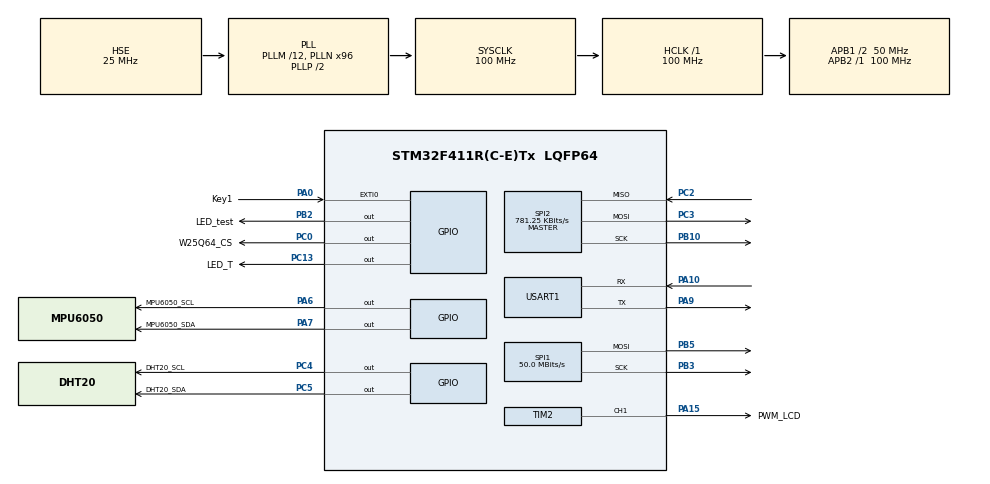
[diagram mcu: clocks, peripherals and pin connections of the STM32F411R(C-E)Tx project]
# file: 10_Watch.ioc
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Dma.Request0=SPI1_TX
Dma.Request1=USART1_RX
Dma.Request2=USART1_TX
Dma.Request3=SPI2_RX
Dma.Request4=SPI2_TX
Dma.SPI1_TX.0.Direction=DMA_MEMORY_TO_PERIPH
Dma.SPI1_TX.0.FIFOMode=DMA_FIFOMODE_DISABLE
Dma.SPI1_TX.0.Instance=DMA2_Stream2
Dma.SPI1_TX.0.MemDataAlignment=DMA_MDATAALIGN_BYTE
Dma.SPI1_TX.0.MemInc=DMA_MINC_ENABLE
Dma.SPI1_TX.0.Mode=DMA_NORMAL
Dma.SPI1_TX.0.PeriphDataAlignment=DMA_PDATAALIGN_BYTE
Dma.SPI1_TX.0.PeriphInc=DMA_PINC_DISABLE
Dma.SPI1_TX.0.Priority=DMA_PRIORITY_LOW
Dma.SPI2_RX.3.Direction=DMA_PERIPH_TO_MEMORY
Dma.SPI2_RX.3.FIFOMode=DMA_FIFOMODE_DISABLE
Dma.SPI2_RX.3.Instance=DMA1_Stream3
Dma.SPI2_RX.3.MemDataAlignment=DMA_MDATAALIGN_BYTE
Dma.SPI2_RX.3.MemInc=DMA_MINC_ENABLE
Dma.SPI2_RX.3.Mode=DMA_NORMAL
Dma.SPI2_RX.3.PeriphDataAlignment=DMA_PDATAALIGN_BYTE
Dma.SPI2_RX.3.PeriphInc=DMA_PINC_DISABLE
Dma.SPI2_RX.3.Priority=DMA_PRIORITY_LOW
Dma.SPI2_TX.4.Direction=DMA_MEMORY_TO_PERIPH
Dma.SPI2_TX.4.FIFOMode=DMA_FIFOMODE_DISABLE
Dma.SPI2_TX.4.Instance=DMA1_Stream4
Dma.SPI2_TX.4.MemDataAlignment=DMA_MDATAALIGN_BYTE
Dma.SPI2_TX.4.MemInc=DMA_MINC_ENABLE
Dma.SPI2_TX.4.Mode=DMA_NORMAL
Dma.SPI2_TX.4.PeriphDataAlignment=DMA_PDATAALIGN_BYTE
Dma.SPI2_TX.4.PeriphInc=DMA_PINC_DISABLE
Dma.SPI2_TX.4.Priority=DMA_PRIORITY_LOW
Dma.USART1_RX.1.Direction=DMA_PERIPH_TO_MEMORY
Dma.USART1_RX.1.FIFOMode=DMA_FIFOMODE_DISABLE
Dma.USART1_RX.1.Instance=DMA2_Stream5
Dma.USART1_RX.1.MemDataAlignment=DMA_MDATAALIGN_BYTE
Dma.USART1_RX.1.MemInc=DMA_MINC_ENABLE
Dma.USART1_RX.1.Mode=DMA_NORMAL
Dma.USART1_RX.1.PeriphDataAlignment=DMA_PDATAALIGN_BYTE
Dma.USART1_RX.1.PeriphInc=DMA_PINC_DISABLE
Dma.USART1_RX.1.Priority=DMA_PRIORITY_LOW
Dma.USART1_TX.2.Direction=DMA_MEMORY_TO_PERIPH
Dma.USART1_TX.2.FIFOMode=DMA_FIFOMODE_DISABLE
Dma.USART1_TX.2.Instance=DMA2_Stream7
Dma.USART1_TX.2.MemDataAlignment=DMA_MDATAALIGN_BYTE
Dma.USART1_TX.2.MemInc=DMA_MINC_ENABLE
Dma.USART1_TX.2.Mode=DMA_NORMAL
Dma.USART1_TX.2.PeriphDataAlignment=DMA_PDATAALIGN_BYTE
Dma.USART1_TX.2.PeriphInc=DMA_PINC_DISABLE
Dma.USART1_TX.2.Priority=DMA_PRIORITY_LOW
FREERTOS.BinarySemaphores01=SerialBinarySem,Dynamic,NULL,Depleted;SPI2_tx_BinarySem,Dynamic,NULL,Available;SPI2_rx_BinarySem,Dynamic,NULL,Available
FREERTOS.Events01=BootEvent,Dynamic,NULL
FREERTOS.Mutexes01=SerialMutex,Dynamic,NULL,Available
FREERTOS.RecursiveMutexes01=W25Q64_RecursiveMutex,Dynamic,NULL,Available
FREERTOS.Tasks01=defaultTask,8,64,StartDefaultTask,Default,NULL,Dynamic,NULL,NULL;KeyTask,41,64,StartKeyTask,As weak,NULL,Dynamic,NULL,NULL;SerialTask,32,128,StartSerialTask,As weak,NULL,Dynamic,NULL,NULL;PageBackTask,40,128,StartPageBackTask,As weak,NULL,Dynamic,NULL,NULL;MsgInbox_Task,24,256,StartMsgInboxTask,As weak,NULL,Dynamic,NULL,NULL;IdleMonitorTask,15,128,StartIdleMonitorTask,As weak,NULL,Dynamic,NULL,NULL;Sleep_Task,8,128,StartSleepTask,As weak,NULL,Dynamic,NULL,NULL;SensorTask,24,512,StartSensorTask,As weak,NULL,Dynamic,NULL,NULL;W25Q64Task,16,1024,StartW25Q64Task,As weak,NULL,Dynamic,NULL,NULL;HardwareInitTask,47,1024,StartHardwareInitTask,As weak,NULL,Dynamic,NULL,NULL;LvHandlerTask,46,1024,StartLvHandlerTask,As weak,NULL,Dynamic,NULL,NULL
FREERTOS.Timers01=IdleTimer,IdleTimerCallback,osTimerPeriodic,As weak,NULL,Dynamic,NULL
FREERTOS.configMAX_TASK_NAME_LEN=32
FREERTOS.configMINIMAL_STACK_SIZE=64
FREERTOS.configTIMER_TASK_PRIORITY=40
FREERTOS.configTOTAL_HEAP_SIZE=32768
FREERTOS.configUSE_TICK_HOOK=1
Mcu.Family=STM32F4
Mcu.Name=STM32F411R(C-E)Tx
Mcu.Package=LQFP64
NVIC.DMA1_Stream3_IRQn=true\:5\:0\:false\:false\:true\:true\:false\:true\:true
NVIC.DMA1_Stream4_IRQn=true\:5\:0\:false\:false\:true\:true\:false\:true\:true
NVIC.DMA2_Stream2_IRQn=true\:5\:0\:false\:false\:true\:true\:false\:true\:true
NVIC.DMA2_Stream5_IRQn=true\:5\:0\:false\:false\:true\:true\:false\:true\:true
NVIC.DMA2_Stream7_IRQn=true\:5\:0\:false\:false\:true\:true\:false\:true\:true
NVIC.EXTI0_IRQn=true\:5\:0\:false\:false\:true\:true\:true\:true\:true
NVIC.PriorityGroup=NVIC_PRIORITYGROUP_4
NVIC.TIM1_TRG_COM_TIM11_IRQn=true\:15\:0\:false\:false\:true\:false\:false\:true\:true
NVIC.TimeBase=TIM1_TRG_COM_TIM11_IRQn
NVIC.TimeBaseIP=TIM11
NVIC.USART1_IRQn=true\:5\:0\:false\:false\:true\:true\:true\:true\:true
PA0-WKUP.GPIO_Label=Key1
PA0-WKUP.GPIO_ModeDefaultEXTI=GPIO_MODE_IT_FALLING
PA0-WKUP.GPIO_PuPd=GPIO_PULLUP
PA0-WKUP.Signal=GPXTI0
PA10.Mode=Asynchronous
PA10.Signal=USART1_RX
PA13.Mode=Serial_Wire
PA13.Signal=SYS_JTMS-SWDIO
PA14.Mode=Serial_Wire
PA14.Signal=SYS_JTCK-SWCLK
PA15.GPIO_Label=PWM_LCD
PA15.Signal=S_TIM2_CH1_ETR
PA6.GPIO_Label=MPU6050_SCL
PA6.Signal=GPIO_Output
PA7.GPIO_Label=MPU6050_SDA
PA7.Signal=GPIO_Output
PA9.Mode=Asynchronous
PA9.Signal=USART1_TX
PB10.GPIO_Speed=GPIO_SPEED_FREQ_HIGH
PB10.Mode=Full_Duplex_Master
PB10.Signal=SPI2_SCK
PB2.GPIO_Label=LED_test
PB2.Signal=GPIO_Output
PB3.GPIO_Speed=GPIO_SPEED_FREQ_VERY_HIGH
PB3.Mode=TX_Only_Simplex_Unidirect_Master
PB3.Signal=SPI1_SCK
PB5.Mode=TX_Only_Simplex_Unidirect_Master
PB5.Signal=SPI1_MOSI
PC0.GPIO_Label=W25Q64_CS
PC0.GPIO_PuPd=GPIO_PULLUP
PC0.PinState=GPIO_PIN_SET
PC0.Signal=GPIO_Output
PC13-ANTI_TAMP.GPIO_Label=LED_T
PC13-ANTI_TAMP.Signal=GPIO_Output
PC14-OSC32_IN.Mode=LSE-External-Oscillator
PC14-OSC32_IN.Signal=RCC_OSC32_IN
PC15-OSC32_OUT.Mode=LSE-External-Oscillator
PC15-OSC32_OUT.Signal=RCC_OSC32_OUT
PC2.GPIO_Speed=GPIO_SPEED_FREQ_HIGH
PC2.Mode=Full_Duplex_Master
PC2.Signal=SPI2_MISO
PC3.GPIO_Speed=GPIO_SPEED_FREQ_HIGH
PC3.Mode=Full_Duplex_Master
PC3.Signal=SPI2_MOSI
PC4.GPIO_Label=DHT20_SCL
PC4.GPIO_ModeDefaultOutputPP=GPIO_MODE_OUTPUT_OD
PC4.GPIO_PuPd=GPIO_PULLUP
PC4.GPIO_Speed=GPIO_SPEED_FREQ_HIGH
PC4.PinState=GPIO_PIN_SET
PC4.Signal=GPIO_Output
PC5.GPIO_Label=DHT20_SDA
PC5.GPIO_ModeDefaultOutputPP=GPIO_MODE_OUTPUT_OD
PC5.GPIO_PuPd=GPIO_PULLUP
PC5.GPIO_Speed=GPIO_SPEED_FREQ_HIGH
PC5.PinState=GPIO_PIN_SET
PC5.Signal=GPIO_Output
PH0\ -\ OSC_IN.Mode=HSE-External-Oscillator
PH0\ -\ OSC_IN.Signal=RCC_OSC_IN
PH1\ -\ OSC_OUT.Mode=HSE-External-Oscillator
PH1\ -\ OSC_OUT.Signal=RCC_OSC_OUT
ProjectManager.HeapSize=0x400
ProjectManager.StackSize=0xE00
ProjectManager.TargetToolchain=CMake
RCC.48MHZClocksFreq_Value=50000000
RCC.AHBFreq_Value=100000000
RCC.APB1CLKDivider=RCC_HCLK_DIV2
RCC.APB1Freq_Value=50000000
RCC.APB1TimFreq_Value=100000000
RCC.APB2Freq_Value=100000000
RCC.APB2TimFreq_Value=100000000
RCC.CortexFreq_Value=100000000
RCC.HCLKFreq_Value=100000000
RCC.HSE_VALUE=25000000
RCC.HSI_VALUE=16000000
RCC.PLLM=12
RCC.PLLN=96
RCC.PLLSourceVirtual=RCC_PLLSOURCE_HSE
RCC.SYSCLKFreq_VALUE=100000000
RCC.SYSCLKSource=RCC_SYSCLKSOURCE_PLLCLK
RCC.VCOOutputFreq_Value=200000000
RTC.Date=15
RTC.Format=RTC_FORMAT_BIN
RTC.Hours=12
RTC.Minutes=35
RTC.Month=RTC_MONTH_OCTOBER
RTC.Year=26
SH.S_TIM2_CH1_ETR.0=TIM2_CH1,PWM Generation1 CH1
SPI1.BaudRatePrescaler=SPI_BAUDRATEPRESCALER_2
SPI1.CLKPhase=SPI_PHASE_2EDGE
SPI1.CLKPolarity=SPI_POLARITY_HIGH
SPI1.CalculateBaudRate=50.0 MBits/s
SPI1.Direction=SPI_DIRECTION_2LINES
SPI1.Mode=SPI_MODE_MASTER
SPI1.VirtualType=VM_MASTER
SPI2.BaudRatePrescaler=SPI_BAUDRATEPRESCALER_64
SPI2.CalculateBaudRate=781.25 KBits/s
SPI2.Direction=SPI_DIRECTION_2LINES
SPI2.Mode=SPI_MODE_MASTER
SPI2.VirtualType=VM_MASTER
TIM2.Channel-PWM\ Generation1\ CH1=TIM_CHANNEL_1
TIM2.Period=300
TIM2.Prescaler=99
USART1.VirtualMode=VM_ASYNC
VP_FREERTOS_VS_CMSIS_V2.Mode=CMSIS_V2
VP_RTC_VS_RTC_Activate.Mode=RTC_Enabled
VP_RTC_VS_RTC_Calendar.Mode=RTC_Calendar
VP_SYS_VS_tim11.Mode=TIM11
VP_TIM2_VS_ClockSourceINT.Mode=Internal
board=custom

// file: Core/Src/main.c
/* USER CODE BEGIN Header */
/**
  ******************************************************************************
  * @file           : main.c
  * @brief          : Main program body
  ******************************************************************************
  * @attention
  *
  * Copyright (c) 2026 STMicroelectronics.
  * All rights reserved.
  *
  * This software is licensed under terms that can be found in the LICENSE file
  * in the root directory of this software component.
  * If no LICENSE file comes with this software, it is provided AS-IS.
  *
  ******************************************************************************
  */
/* USER CODE END Header */
#include "main.h"
#include "cmsis_os.h"
#include "dma.h"
#include "rtc.h"
#include "spi.h"
#include "tim.h"
#include "usart.h"
#include "gpio.h"

void SystemClock_Config(void);
void MX_FREERTOS_Init(void);

int main(void)
{

  /* MCU Configuration--------------------------------------------------------*/

  /* Reset of all peripherals, Initializes the Flash interface and the Systick. */
  HAL_Init();
  /* USER CODE BEGIN Init */
  //HAL_DBGMCU_EnableDBGStopMode();   /* 允许调试器在 STOP 模式下 halt 内核 */
  /* USER CODE END Init */

  /* Configure the system clock */
  SystemClock_Config();

  /* Initialize all configured peripherals */
  MX_GPIO_Init();
  MX_DMA_Init();
  MX_SPI1_Init();
  MX_USART1_UART_Init();
  MX_RTC_Init();
  MX_TIM2_Init();
  MX_SPI2_Init();

  /* Init scheduler */
  osKernelInitialize();  /* Call init function for freertos objects (in cmsis_os2.c) */
  MX_FREERTOS_Init();

  /* Start scheduler */
  osKernelStart();

  /* We should never get here as control is now taken by the scheduler */

  /* Infinite loop */
  while (1)
  {

  }
}

void SystemClock_Config(void)
{
  RCC_OscInitTypeDef RCC_OscInitStruct = {0};
  RCC_ClkInitTypeDef RCC_ClkInitStruct = {0};

  /** Configure the main internal regulator output voltage
  */
  __HAL_RCC_PWR_CLK_ENABLE();
  __HAL_PWR_VOLTAGESCALING_CONFIG(PWR_REGULATOR_VOLTAGE_SCALE1);

  /** Initializes the RCC Oscillators according to the specified parameters
  * in the RCC_OscInitTypeDef structure.
  */
  RCC_OscInitStruct.OscillatorType = RCC_OSCILLATORTYPE_LSI|RCC_OSCILLATORTYPE_HSE;
  RCC_OscInitStruct.HSEState = RCC_HSE_ON;
  RCC_OscInitStruct.LSIState = RCC_LSI_ON;
  RCC_OscInitStruct.PLL.PLLState = RCC_PLL_ON;
  RCC_OscInitStruct.PLL.PLLSource = RCC_PLLSOURCE_HSE;
  RCC_OscInitStruct.PLL.PLLM = 12;
  RCC_OscInitStruct.PLL.PLLN = 96;
  RCC_OscInitStruct.PLL.PLLP = RCC_PLLP_DIV2;
  RCC_OscInitStruct.PLL.PLLQ = 4;
  if (HAL_RCC_OscConfig(&RCC_OscInitStruct) != HAL_OK)
  {
    Error_Handler();
  }

  /** Initializes the CPU, AHB and APB buses clocks
  */
  RCC_ClkInitStruct.ClockType = RCC_CLOCKTYPE_HCLK|RCC_CLOCKTYPE_SYSCLK
                              |RCC_CLOCKTYPE_PCLK1|RCC_CLOCKTYPE_PCLK2;
  RCC_ClkInitStruct.SYSCLKSource = RCC_SYSCLKSOURCE_PLLCLK;
  RCC_ClkInitStruct.AHBCLKDivider = RCC_SYSCLK_DIV1;
  RCC_ClkInitStruct.APB1CLKDivider = RCC_HCLK_DIV2;
  RCC_ClkInitStruct.APB2CLKDivider = RCC_HCLK_DIV1;

  if (HAL_RCC_ClockConfig(&RCC_ClkInitStruct, FLASH_LATENCY_3) != HAL_OK)
  {
    Error_Handler();
  }
}

void HAL_TIM_PeriodElapsedCallback(TIM_HandleTypeDef *htim)
{
  if (htim->Instance == TIM11)
  {
    HAL_IncTick();
  }
}

void Error_Handler(void)
{
  __disable_irq();
  while (1)
  {
  }
}

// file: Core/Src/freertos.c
/* USER CODE BEGIN Header */
/**
  ******************************************************************************
  * File Name          : freertos.c
  * Description        : Code for freertos applications
  ******************************************************************************
  * @attention
  *
  * Copyright (c) 2026 STMicroelectronics.
  * All rights reserved.
  *
  * This software is licensed under terms that can be found in the LICENSE file
  * in the root directory of this software component.
  * If no LICENSE file comes with this software, it is provided AS-IS.
  *
  ******************************************************************************
  */
/* USER CODE END Header */

#include "FreeRTOS.h"
#include "task.h"
#include "main.h"
#include "cmsis_os.h"

/* USER CODE BEGIN Includes */
#include "user_TasksInit.h"
#include "LVGLTask.h"
#include "W25Q64.h"
#include "SerialTask.h"
#include "lvgl.h"
/* USER CODE END Includes */

/* USER CODE BEGIN Variables */
osMessageQueueId_t W25Q64QueueHandle;
/* USER CODE END Variables */
/* Definitions for defaultTask */
osThreadId_t defaultTaskHandle;
const osThreadAttr_t defaultTask_attributes = {
  .name = "defaultTask",
  .stack_size = 64 * 4,
  .priority = (osPriority_t) osPriorityLow,
};
/* Definitions for KeyTask */
osThreadId_t KeyTaskHandle;
const osThreadAttr_t KeyTask_attributes = {
  .name = "KeyTask",
  .stack_size = 64 * 4,
  .priority = (osPriority_t) osPriorityHigh1,
};
/* Definitions for SerialTask */
osThreadId_t SerialTaskHandle;
const osThreadAttr_t SerialTask_attributes = {
  .name = "SerialTask",
  .stack_size = 128 * 4,
  .priority = (osPriority_t) osPriorityAboveNormal,
};
/* Definitions for PageBackTask */
osThreadId_t PageBackTaskHandle;
const osThreadAttr_t PageBackTask_attributes = {
  .name = "PageBackTask",
  .stack_size = 128 * 4,
  .priority = (osPriority_t) osPriorityHigh,
};
/* Definitions for MsgInbox_Task */
osThreadId_t MsgInbox_TaskHandle;
const osThreadAttr_t MsgInbox_Task_attributes = {
  .name = "MsgInbox_Task",
  .stack_size = 256 * 4,
  .priority = (osPriority_t) osPriorityNormal,
};
/* Definitions for IdleMonitorTask */
osThreadId_t IdleMonitorTaskHandle;
const osThreadAttr_t IdleMonitorTask_attributes = {
  .name = "IdleMonitorTask",
  .stack_size = 128 * 4,
  .priority = (osPriority_t) osPriorityLow7,
};
/* Definitions for Sleep_Task */
osThreadId_t Sleep_TaskHandle;
const osThreadAttr_t Sleep_Task_attributes = {
  .name = "Sleep_Task",
  .stack_size = 128 * 4,
  .priority = (osPriority_t) osPriorityLow,
};
/* Definitions for SensorTask */
osThreadId_t SensorTaskHandle;
const osThreadAttr_t SensorTask_attributes = {
  .name = "SensorTask",
  .stack_size = 512 * 4,
  .priority = (osPriority_t) osPriorityNormal,
};
/* Definitions for W25Q64Task */
osThreadId_t W25Q64TaskHandle;
const osThreadAttr_t W25Q64Task_attributes = {
  .name = "W25Q64Task",
  .stack_size = 1024 * 4,
  .priority = (osPriority_t) osPriorityBelowNormal,
};
/* Definitions for HardwareInitTask */
osThreadId_t HardwareInitTaskHandle;
const osThreadAttr_t HardwareInitTask_attributes = {
  .name = "HardwareInitTask",
  .stack_size = 1024 * 4,
  .priority = (osPriority_t) osPriorityHigh7,
};
/* Definitions for LvHandlerTask */
osThreadId_t LvHandlerTaskHandle;
const osThreadAttr_t LvHandlerTask_attributes = {
  .name = "LvHandlerTask",
  .stack_size = 1024 * 4,
  .priority = (osPriority_t) osPriorityHigh6,
};
/* Definitions for IdleTimer */
osTimerId_t IdleTimerHandle;
const osTimerAttr_t IdleTimer_attributes = {
  .name = "IdleTimer"
};
/* Definitions for SerialMutex */
osMutexId_t SerialMutexHandle;
const osMutexAttr_t SerialMutex_attributes = {
  .name = "SerialMutex"
};
/* Definitions for W25Q64_RecursiveMutex */
osMutexId_t W25Q64_RecursiveMutexHandle;
const osMutexAttr_t W25Q64_RecursiveMutex_attributes = {
  .name = "W25Q64_RecursiveMutex",
  .attr_bits = osMutexRecursive,
};
/* Definitions for SerialBinarySem */
osSemaphoreId_t SerialBinarySemHandle;
const osSemaphoreAttr_t SerialBinarySem_attributes = {
  .name = "SerialBinarySem"
};
/* Definitions for SPI2_tx_BinarySem */
osSemaphoreId_t SPI2_tx_BinarySemHandle;
const osSemaphoreAttr_t SPI2_tx_BinarySem_attributes = {
  .name = "SPI2_tx_BinarySem"
};
/* Definitions for SPI2_rx_BinarySem */
osSemaphoreId_t SPI2_rx_BinarySemHandle;
const osSemaphoreAttr_t SPI2_rx_BinarySem_attributes = {
  .name = "SPI2_rx_BinarySem"
};
/* Definitions for BootEvent */
osEventFlagsId_t BootEventHandle;
const osEventFlagsAttr_t BootEvent_attributes = {
  .name = "BootEvent"
};

void StartDefaultTask(void *argument);
void StartKeyTask(void *argument);
void StartSerialTask(void *argument);
void StartPageBackTask(void *argument);
void StartMsgInboxTask(void *argument);
void StartIdleMonitorTask(void *argument);
void StartSleepTask(void *argument);
void StartSensorTask(void *argument);
void StartW25Q64Task(void *argument);
void StartHardwareInitTask(void *argument);
void StartLvHandlerTask(void *argument);
void IdleTimerCallback(void *argument);

void MX_FREERTOS_Init(void); /* (MISRA C 2004 rule 8.1) */

/* Hook prototypes */
void vApplicationTickHook(void);

/* USER CODE BEGIN 3 */
void vApplicationTickHook( void )
{
   /* This function will be called by each tick interrupt if
   configUSE_TICK_HOOK is set to 1 in FreeRTOSConfig.h. User code can be
   added here, but the tick hook is called from an interrupt context, so
   code must not attempt to block, and only the interrupt safe FreeRTOS API
   functions can be used (those that end in FromISR()). */
  TaskTickHook();
}
/* USER CODE END 3 */

void MX_FREERTOS_Init(void) {
  /* Create the mutex(es) */
  /* creation of SerialMutex */
  SerialMutexHandle = osMutexNew(&SerialMutex_attributes);

  /* Create the recursive mutex(es) */
  /* creation of W25Q64_RecursiveMutex */
  W25Q64_RecursiveMutexHandle = osMutexNew(&W25Q64_RecursiveMutex_attributes);

  /* Create the semaphores(s) */
  /* creation of SerialBinarySem */
  SerialBinarySemHandle = osSemaphoreNew(1, 0, &SerialBinarySem_attributes);

  /* creation of SPI2_tx_BinarySem */
  SPI2_tx_BinarySemHandle = osSemaphoreNew(1, 1, &SPI2_tx_BinarySem_attributes);

  /* creation of SPI2_rx_BinarySem */
  SPI2_rx_BinarySemHandle = osSemaphoreNew(1, 1, &SPI2_rx_BinarySem_attributes);

  /* Create the timer(s) */
  /* creation of IdleTimer */
  IdleTimerHandle = osTimerNew(IdleTimerCallback, osTimerPeriodic, NULL, &IdleTimer_attributes);

  /* USER CODE BEGIN RTOS_TIMERS */
  /* start timers, add new ones, ... */
  osTimerStart(IdleTimerHandle, 100);//100ms
  /* USER CODE END RTOS_TIMERS */

  /* USER CODE BEGIN RTOS_QUEUES */
  /* add queues, ... */

  const osMessageQueueAttr_t W25Q64Queue_attributes = {
    .name = "W25Q64Queue"
  };
  W25Q64QueueHandle = osMessageQueueNew(16,sizeof(StorageReq_t),&W25Q64Queue_attributes);
  /* USER CODE END RTOS_QUEUES */

  /* Create the thread(s) */
  /* creation of defaultTask */
  defaultTaskHandle = osThreadNew(StartDefaultTask, NULL, &defaultTask_attributes);

  /* creation of KeyTask */
  KeyTaskHandle = osThreadNew(StartKeyTask, NULL, &KeyTask_attributes);

  /* creation of SerialTask */
  SerialTaskHandle = osThreadNew(StartSerialTask, NULL, &SerialTask_attributes);

  /* creation of PageBackTask */
  PageBackTaskHandle = osThreadNew(StartPageBackTask, NULL, &PageBackTask_attributes);

  /* creation of MsgInbox_Task */
  MsgInbox_TaskHandle = osThreadNew(StartMsgInboxTask, NULL, &MsgInbox_Task_attributes);

  /* creation of IdleMonitorTask */
  IdleMonitorTaskHandle = osThreadNew(StartIdleMonitorTask, NULL, &IdleMonitorTask_attributes);

  /* creation of Sleep_Task */
  Sleep_TaskHandle = osThreadNew(StartSleepTask, NULL, &Sleep_Task_attributes);

  /* creation of SensorTask */
  SensorTaskHandle = osThreadNew(StartSensorTask, NULL, &SensorTask_attributes);

  /* creation of W25Q64Task */
  W25Q64TaskHandle = osThreadNew(StartW25Q64Task, NULL, &W25Q64Task_attributes);

  /* creation of HardwareInitTask */
  HardwareInitTaskHandle = osThreadNew(StartHardwareInitTask, NULL, &HardwareInitTask_attributes);

  /* creation of LvHandlerTask */
  LvHandlerTaskHandle = osThreadNew(StartLvHandlerTask, NULL, &LvHandlerTask_attributes);

  /* creation of BootEvent */
  BootEventHandle = osEventFlagsNew(&BootEvent_attributes);

}

void StartDefaultTask(void *argument)
{
  /* USER CODE BEGIN StartDefaultTask */
  lv_mem_monitor_t lv_mon;
  /* Infinite loop */
  for(;;)
  {
    //监控内存使用情况
    // lv_mem_monitor(&lv_mon);
    // Serial_Printf("[MEM] LVGL used:%u total:%u max:%u frag:%u%% | FreeRTOS free:%u min:%u\r\n",
    //               (unsigned)(lv_mon.total_size - lv_mon.free_size),
    //               (unsigned)lv_mon.total_size,
    //               (unsigned)lv_mon.max_used,
    //               (unsigned)lv_mon.frag_pct,
    //               (unsigned)xPortGetFreeHeapSize(),
    //               (unsigned)xPortGetMinimumEverFreeHeapSize());
    //
    osDelay(5000);
  }
  /* USER CODE END StartDefaultTask */
}

__weak void StartKeyTask(void *argument)
{
  for(;;)
  {
    osDelay(1);
  }
}

__weak void StartSerialTask(void *argument)
{
  for(;;)
  {
    osDelay(1);
  }
}

__weak void StartPageBackTask(void *argument)
{
  for(;;)
  {
    osDelay(1);
  }
}

__weak void StartMsgInboxTask(void *argument)
{
  for(;;)
  {
    osDelay(1);
  }
}

__weak void StartIdleMonitorTask(void *argument)
{
  for(;;)
  {
    osDelay(1);
  }
}

__weak void StartSleepTask(void *argument)
{
  for(;;)
  {
    osDelay(1);
  }
}

__weak void StartSensorTask(void *argument)
{
  for(;;)
  {
    osDelay(1);
  }
}

__weak void StartW25Q64Task(void *argument)
{
  for(;;)
  {
    osDelay(1);
  }
}

__weak void StartHardwareInitTask(void *argument)
{
  for(;;)
  {
    osDelay(1);
  }
}

__weak void StartLvHandlerTask(void *argument)
{
  for(;;)
  {
    osDelay(1);
  }
}

/* IdleTimerCallback function */
__weak void IdleTimerCallback(void *argument)
{
}
